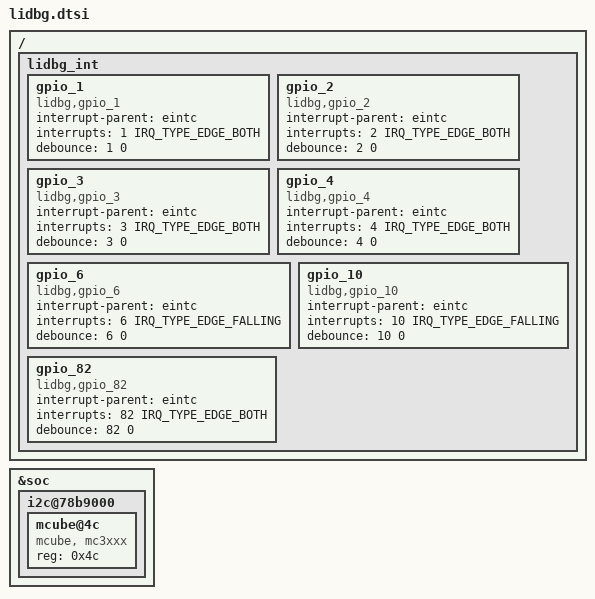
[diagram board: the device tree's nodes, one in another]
/ {
	lidbg_int {
		//button1
		gpio_1 {
			compatible = "lidbg,gpio_1";
			interrupt-parent = <&eintc>;
			interrupts = <1 IRQ_TYPE_EDGE_BOTH>;
			debounce = <1 0>;
		};
		//button2
		gpio_2 {
			compatible = "lidbg,gpio_2";
			interrupt-parent = <&eintc>;
			interrupts = <2 IRQ_TYPE_EDGE_BOTH>;
			debounce = <2 0>;
		};
		//button3
		gpio_3 {
			compatible = "lidbg,gpio_3";
			interrupt-parent = <&eintc>;
			interrupts = <3 IRQ_TYPE_EDGE_BOTH>;
			debounce = <3 0>;
		};
		//button4
		gpio_4 {
			compatible = "lidbg,gpio_4";
			interrupt-parent = <&eintc>;
			interrupts = <4 IRQ_TYPE_EDGE_BOTH>;
			debounce = <4 0>;
		};
		//i2c_c
		gpio_6 {
			compatible = "lidbg,gpio_6";
			interrupt-parent = <&eintc>;
			interrupts = <6 IRQ_TYPE_EDGE_FALLING>;
			debounce = <6 0>;
		};
		//ts_int
		gpio_10 {
			compatible = "lidbg,gpio_10";
			interrupt-parent = <&eintc>;
			interrupts = <10 IRQ_TYPE_EDGE_FALLING>;
			debounce = <10 0>;
		};
		//request_fastboot
		gpio_82 {
			compatible = "lidbg,gpio_82";
			interrupt-parent = <&eintc>;
			interrupts = <82 IRQ_TYPE_EDGE_BOTH>;
			debounce = <82 0>;
		};
	};
};


&soc {
		i2c@78b9000 {
			mcube@4c {
				compatible = "mcube, mc3xxx";
				reg = <0x4c>;
			};
		};

		/*i2c@78b9000 {
			bosch@18 {
				compatible = "bosch, bma2x2";
				reg = <0x18>;
			};
		};*/
};
